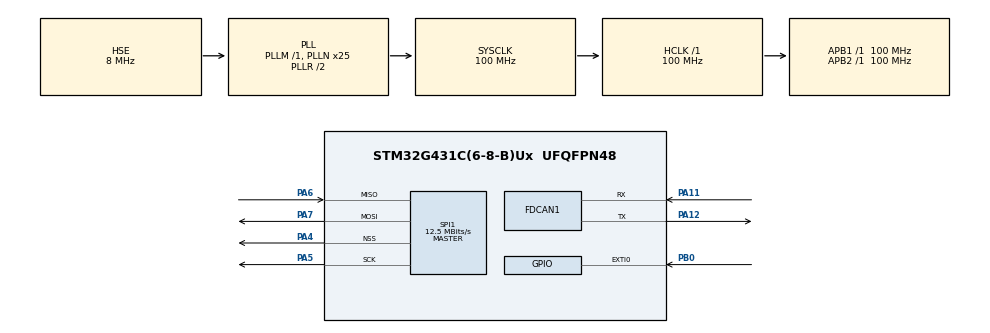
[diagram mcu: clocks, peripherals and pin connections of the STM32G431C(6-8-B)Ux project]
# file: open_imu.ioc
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FDCAN1.CalculateBaudRateNominal=1000000
FDCAN1.CalculateTimeBitNominal=1000
FDCAN1.CalculateTimeQuantumNominal=100.0
FREERTOS.Tasks01=defaultTask,24,128,StartDefaultTask,Default,NULL,Dynamic,NULL,NULL
FREERTOS.configUSE_NEWLIB_REENTRANT=1
Mcu.Family=STM32G4
Mcu.Name=STM32G431C(6-8-B)Ux
Mcu.Package=UFQFPN48
NVIC.PriorityGroup=NVIC_PRIORITYGROUP_4
NVIC.TIM6_DAC_IRQn=true\:15\:0\:false\:false\:true\:false\:false\:true\:true
NVIC.TimeBase=TIM6_DAC_IRQn
NVIC.TimeBaseIP=TIM6
PA11.Mode=FDCAN_Activate
PA11.Signal=FDCAN1_RX
PA12.Mode=FDCAN_Activate
PA12.Signal=FDCAN1_TX
PA13.Mode=Serial_Wire
PA13.Signal=SYS_JTMS-SWDIO
PA14.Mode=Serial_Wire
PA14.Signal=SYS_JTCK-SWCLK
PA4.Mode=NSS_Signal_Hard_Output
PA4.Signal=SPI1_NSS
PA5.Mode=Full_Duplex_Master
PA5.Signal=SPI1_SCK
PA6.Mode=Full_Duplex_Master
PA6.Signal=SPI1_MISO
PA7.Mode=Full_Duplex_Master
PA7.Signal=SPI1_MOSI
PB0.Signal=GPXTI0
PF0-OSC_IN.Mode=HSE-External-Oscillator
PF0-OSC_IN.Signal=RCC_OSC_IN
PF1-OSC_OUT.Mode=HSE-External-Oscillator
PF1-OSC_OUT.Signal=RCC_OSC_OUT
ProjectManager.HeapSize=0x200
ProjectManager.StackSize=0x400
ProjectManager.TargetToolchain=STM32CubeIDE
RCC.ADC12Freq_Value=100000000
RCC.AHBFreq_Value=100000000
RCC.APB1Freq_Value=100000000
RCC.APB1TimFreq_Value=100000000
RCC.APB2Freq_Value=100000000
RCC.APB2TimFreq_Value=100000000
RCC.CortexFreq_Value=100000000
RCC.EXTERNAL_CLOCK_VALUE=12288000
RCC.HCLKFreq_Value=100000000
RCC.HSE_VALUE=8000000
RCC.HSI48_VALUE=48000000
RCC.HSI_VALUE=16000000
RCC.LSE_VALUE=32768
RCC.PLLN=25
RCC.PLLSourceVirtual=RCC_PLLSOURCE_HSE
RCC.SYSCLKFreq_VALUE=100000000
RCC.SYSCLKSource=RCC_SYSCLKSOURCE_PLLCLK
RCC.USBFreq_Value=100000000
RCC.VCOOutputFreq_Value=200000000
SPI1.CalculateBaudRate=12.5 MBits/s
SPI1.Direction=SPI_DIRECTION_2LINES
SPI1.Mode=SPI_MODE_MASTER
SPI1.VirtualNSS=VM_NSSHARD
SPI1.VirtualType=VM_MASTER
VP_FREERTOS_VS_CMSIS_V2.Mode=CMSIS_V2
VP_SYS_VS_DBSignals.Mode=DisableDeadBatterySignals
VP_SYS_VS_tim6.Mode=TIM6
board=custom

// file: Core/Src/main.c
/* USER CODE BEGIN Header */
/**
  ******************************************************************************
  * @file           : main.c
  * @brief          : Main program body
  ******************************************************************************
  * @attention
  *
  * Copyright (c) 2026 STMicroelectronics.
  * All rights reserved.
  *
  * This software is licensed under terms that can be found in the LICENSE file
  * in the root directory of this software component.
  * If no LICENSE file comes with this software, it is provided AS-IS.
  *
  ******************************************************************************
  */
/* USER CODE END Header */
#include "main.h"
#include "cmsis_os.h"

/* USER CODE BEGIN Includes */
#include "imu_sync.h"
#include "imu_task.h"
/* USER CODE END Includes */

FDCAN_HandleTypeDef hfdcan1;

SPI_HandleTypeDef hspi1;

/* Definitions for defaultTask */
osThreadId_t defaultTaskHandle;
const osThreadAttr_t defaultTask_attributes = {
  .name = "defaultTask",
  .priority = (osPriority_t) osPriorityNormal,
  .stack_size = 128 * 4
};

void SystemClock_Config(void);
static void MX_GPIO_Init(void);
static void MX_FDCAN1_Init(void);
static void MX_SPI1_Init(void);
void StartDefaultTask(void *argument);

int main(void)
{

  /* MCU Configuration--------------------------------------------------------*/

  /* Reset of all peripherals, Initializes the Flash interface and the Systick. */
  HAL_Init();

  /* Configure the system clock */
  SystemClock_Config();

  /* Initialize all configured peripherals */
  MX_GPIO_Init();
  MX_FDCAN1_Init();
  MX_SPI1_Init();

  /* Init scheduler */
  osKernelInitialize();

  /* Create the thread(s) */
  /* creation of defaultTask */
  defaultTaskHandle = osThreadNew(StartDefaultTask, NULL, &defaultTask_attributes);

  /* USER CODE BEGIN RTOS_THREADS */
  /* add threads, ... */
  /* Start the IMU data-acquisition / CAN FD transmission task */
  IMU_StartTask();
  /* USER CODE END RTOS_THREADS */

  /* Start scheduler */
  osKernelStart();

  /* We should never get here as control is now taken by the scheduler */

  /* Infinite loop */
  while (1)
  {

  }
}

void SystemClock_Config(void)
{
  RCC_OscInitTypeDef RCC_OscInitStruct = {0};
  RCC_ClkInitTypeDef RCC_ClkInitStruct = {0};

  /** Configure the main internal regulator output voltage
  */
  HAL_PWREx_ControlVoltageScaling(PWR_REGULATOR_VOLTAGE_SCALE1);

  /** Initializes the RCC Oscillators according to the specified parameters
  * in the RCC_OscInitTypeDef structure.
  */
  RCC_OscInitStruct.OscillatorType = RCC_OSCILLATORTYPE_HSE;
  RCC_OscInitStruct.HSEState = RCC_HSE_ON;
  RCC_OscInitStruct.PLL.PLLState = RCC_PLL_ON;
  RCC_OscInitStruct.PLL.PLLSource = RCC_PLLSOURCE_HSE;
  RCC_OscInitStruct.PLL.PLLM = RCC_PLLM_DIV1;
  RCC_OscInitStruct.PLL.PLLN = 25;
  RCC_OscInitStruct.PLL.PLLP = RCC_PLLP_DIV2;
  RCC_OscInitStruct.PLL.PLLQ = RCC_PLLQ_DIV2;
  RCC_OscInitStruct.PLL.PLLR = RCC_PLLR_DIV2;
  if (HAL_RCC_OscConfig(&RCC_OscInitStruct) != HAL_OK)
  {
    Error_Handler();
  }

  /** Initializes the CPU, AHB and APB buses clocks
  */
  RCC_ClkInitStruct.ClockType = RCC_CLOCKTYPE_HCLK|RCC_CLOCKTYPE_SYSCLK
                              |RCC_CLOCKTYPE_PCLK1|RCC_CLOCKTYPE_PCLK2;
  RCC_ClkInitStruct.SYSCLKSource = RCC_SYSCLKSOURCE_PLLCLK;
  RCC_ClkInitStruct.AHBCLKDivider = RCC_SYSCLK_DIV1;
  RCC_ClkInitStruct.APB1CLKDivider = RCC_HCLK_DIV1;
  RCC_ClkInitStruct.APB2CLKDivider = RCC_HCLK_DIV1;

  if (HAL_RCC_ClockConfig(&RCC_ClkInitStruct, FLASH_LATENCY_3) != HAL_OK)
  {
    Error_Handler();
  }
}

static void MX_FDCAN1_Init(void)
{

  hfdcan1.Instance = FDCAN1;
    /* CAN FD with bit-rate switching: nominal 1 Mbit/s, data 5 Mbit/s.
     FDCAN kernel clock = 100 MHz (PCLK1, FDCAN_CLOCK_DIV1).
     Nominal: prescaler 10 -> 100 ns/tq, (1+7+2) tq = 1 us -> 1 Mbit/s, SP 80%.
     Data   : prescaler 4  ->  40 ns/tq, (1+3+1) tq = 200 ns -> 5 Mbit/s, SP 80%. */
  hfdcan1.Init.ClockDivider = FDCAN_CLOCK_DIV1;
  /* CAN FD with BRS: nominal 1 Mbit/s, data 5 Mbit/s. */
  hfdcan1.Init.FrameFormat = FDCAN_FRAME_FD_BRS;
  hfdcan1.Init.Mode = FDCAN_MODE_NORMAL;
  hfdcan1.Init.AutoRetransmission = DISABLE;
  hfdcan1.Init.TransmitPause = DISABLE;
  hfdcan1.Init.ProtocolException = DISABLE;
  hfdcan1.Init.NominalPrescaler = 10;
  hfdcan1.Init.NominalSyncJumpWidth = 2;
  hfdcan1.Init.NominalTimeSeg1 = 7;
  hfdcan1.Init.NominalTimeSeg2 = 2;
  hfdcan1.Init.DataPrescaler = 4;
  hfdcan1.Init.DataSyncJumpWidth = 1;
  hfdcan1.Init.DataTimeSeg1 = 3;
  hfdcan1.Init.DataTimeSeg2 = 1;
  hfdcan1.Init.StdFiltersNbr = 0;
  hfdcan1.Init.ExtFiltersNbr = 0;
  hfdcan1.Init.TxFifoQueueMode = FDCAN_TX_FIFO_OPERATION;
  if (HAL_FDCAN_Init(&hfdcan1) != HAL_OK)
  {
    Error_Handler();
  }
  /* USER CODE BEGIN FDCAN1_Init 2 */
#if OPENIMU_CAN_SYNC
  /* Apply the optional filter allocation in a CubeMX-preserved section.
   * The controller has not been started; reinitialize its configuration only. */
  hfdcan1.Init.StdFiltersNbr = 1U;
  if (HAL_FDCAN_Init(&hfdcan1) != HAL_OK)
  {
    Error_Handler();
  }
#endif

  /* USER CODE END FDCAN1_Init 2 */

}

static void MX_SPI1_Init(void)
{

  /* SPI1 parameter configuration*/
  hspi1.Instance = SPI1;
  hspi1.Init.Mode = SPI_MODE_MASTER;
  hspi1.Init.Direction = SPI_DIRECTION_2LINES;
  /* ICM-45686 requires 8-bit transfers (fix CubeMX default of 4-bit). */
  hspi1.Init.DataSize = SPI_DATASIZE_8BIT;
  /* SPI Mode 3 (CPOL=High, CPHA=2Edge) - matches the working BeijingDynamics /
   * open_sprite_runtime reference driver. */
  hspi1.Init.CLKPolarity = SPI_POLARITY_HIGH;
  hspi1.Init.CLKPhase = SPI_PHASE_2EDGE;
  /* Software NSS: CS (PA4) is toggled manually in the driver. */
  hspi1.Init.NSS = SPI_NSS_SOFT;
  /* 12.5 MHz (100 MHz / 8); half of the ICM-45686 24 MHz SPI limit. */
  hspi1.Init.BaudRatePrescaler = SPI_BAUDRATEPRESCALER_8;
  hspi1.Init.FirstBit = SPI_FIRSTBIT_MSB;
  hspi1.Init.TIMode = SPI_TIMODE_DISABLE;
  hspi1.Init.CRCCalculation = SPI_CRCCALCULATION_DISABLE;
  hspi1.Init.CRCPolynomial = 7;
  hspi1.Init.CRCLength = SPI_CRC_LENGTH_DATASIZE;
  /* NSS must stay low for the whole burst read/write (no inter-byte pulse). */
  hspi1.Init.NSSPMode = SPI_NSS_PULSE_DISABLE;
  if (HAL_SPI_Init(&hspi1) != HAL_OK)
  {
    Error_Handler();
  }

}

static void MX_GPIO_Init(void)
{
  GPIO_InitTypeDef GPIO_InitStruct = {0};

  /* GPIO Ports Clock Enable */
  __HAL_RCC_GPIOC_CLK_ENABLE();
  __HAL_RCC_GPIOF_CLK_ENABLE();
  __HAL_RCC_GPIOG_CLK_ENABLE();
  __HAL_RCC_GPIOA_CLK_ENABLE();
  __HAL_RCC_GPIOB_CLK_ENABLE();

  /*Configure GPIO pins : PC13 PC14 PC15 PC4
                           PC6 PC10 PC11 */
  GPIO_InitStruct.Pin = GPIO_PIN_13|GPIO_PIN_14|GPIO_PIN_15|GPIO_PIN_4
                          |GPIO_PIN_6|GPIO_PIN_10|GPIO_PIN_11;
  GPIO_InitStruct.Mode = GPIO_MODE_ANALOG;
  GPIO_InitStruct.Pull = GPIO_NOPULL;
  HAL_GPIO_Init(GPIOC, &GPIO_InitStruct);

  /*Configure GPIO pin : PG10 */
  GPIO_InitStruct.Pin = GPIO_PIN_10;
  GPIO_InitStruct.Mode = GPIO_MODE_ANALOG;
  GPIO_InitStruct.Pull = GPIO_NOPULL;
  HAL_GPIO_Init(GPIOG, &GPIO_InitStruct);

  /*Configure GPIO pins : PA0 PA1 PA2 PA3
                           PA8 PA9 PA10 PA15 */
  GPIO_InitStruct.Pin = GPIO_PIN_0|GPIO_PIN_1|GPIO_PIN_2|GPIO_PIN_3
                          |GPIO_PIN_8|GPIO_PIN_9|GPIO_PIN_10|GPIO_PIN_15;
  GPIO_InitStruct.Mode = GPIO_MODE_ANALOG;
  GPIO_InitStruct.Pull = GPIO_NOPULL;
  HAL_GPIO_Init(GPIOA, &GPIO_InitStruct);

  /*Configure GPIO pin : PA4 (IMU chip-select, software-controlled) */
  GPIO_InitStruct.Pin = GPIO_PIN_4;
  GPIO_InitStruct.Mode = GPIO_MODE_OUTPUT_PP;
  GPIO_InitStruct.Pull = GPIO_NOPULL;
  GPIO_InitStruct.Speed = GPIO_SPEED_FREQ_LOW;
  HAL_GPIO_Init(GPIOA, &GPIO_InitStruct);
  HAL_GPIO_WritePin(GPIOA, GPIO_PIN_4, GPIO_PIN_SET); /* CS idle high (de-asserted) */

  /*Configure GPIO pin : PB0 */
  GPIO_InitStruct.Pin = GPIO_PIN_0;
  GPIO_InitStruct.Mode = GPIO_MODE_IT_RISING;
  GPIO_InitStruct.Pull = GPIO_NOPULL;
  HAL_GPIO_Init(GPIOB, &GPIO_InitStruct);

  /*Configure GPIO pins : PB1 PB10 PB11
                           PB12 PB13 PB14 PB15
                           PB3 PB4 PB5 PB6
                           PB7 PB8 PB9 */
  GPIO_InitStruct.Pin = GPIO_PIN_1|GPIO_PIN_10|GPIO_PIN_11
                          |GPIO_PIN_12|GPIO_PIN_13|GPIO_PIN_14|GPIO_PIN_15
                          |GPIO_PIN_3|GPIO_PIN_4|GPIO_PIN_5|GPIO_PIN_6
                          |GPIO_PIN_7|GPIO_PIN_8|GPIO_PIN_9;
  GPIO_InitStruct.Mode = GPIO_MODE_ANALOG;
  GPIO_InitStruct.Pull = GPIO_NOPULL;
  HAL_GPIO_Init(GPIOB, &GPIO_InitStruct);

  /*Configure GPIO pin : PB2 (status LED, current-sinking: LOW = ON) */
  GPIO_InitStruct.Pin = GPIO_PIN_2;
  GPIO_InitStruct.Mode = GPIO_MODE_OUTPUT_PP;
  GPIO_InitStruct.Pull = GPIO_NOPULL;
  GPIO_InitStruct.Speed = GPIO_SPEED_FREQ_LOW;
  HAL_GPIO_Init(GPIOB, &GPIO_InitStruct);

}

void StartDefaultTask(void *argument)
{
  for(;;)
  {
    osDelay(1);
  }
}

void HAL_TIM_PeriodElapsedCallback(TIM_HandleTypeDef *htim)
{
  if (htim->Instance == TIM6)
  {
    HAL_IncTick();
  }
}

void Error_Handler(void)
{
  __disable_irq();
  while (1)
  {
  }
}
